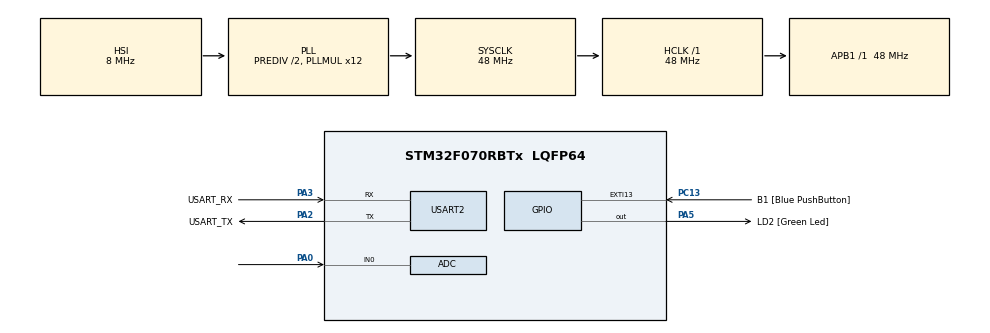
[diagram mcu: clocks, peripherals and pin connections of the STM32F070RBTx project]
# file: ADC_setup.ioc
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ADC.SamplingTime=ADC_SAMPLETIME_71CYCLES_5
Mcu.Family=STM32F0
Mcu.Name=STM32F070RBTx
Mcu.Package=LQFP64
PA0.Mode=IN0
PA0.Signal=ADC_IN0
PA13.GPIO_Label=TMS
PA13.Mode=Serial_Wire
PA13.Signal=SYS_SWDIO
PA14.GPIO_Label=TCK
PA14.Mode=Serial_Wire
PA14.Signal=SYS_SWCLK
PA2.GPIO_Label=USART_TX
PA2.Mode=Asynchronous
PA2.Signal=USART2_TX
PA3.GPIO_Label=USART_RX
PA3.Mode=Asynchronous
PA3.Signal=USART2_RX
PA5.GPIO_Label=LD2 [Green Led]
PA5.Signal=GPIO_Output
PC13.GPIO_Label=B1 [Blue PushButton]
PC13.GPIO_ModeDefaultEXTI=GPIO_MODE_IT_FALLING
PC13.Signal=GPXTI13
PC14-OSC32_IN.GPIO_Label=RCC_OSC32_IN
PC14-OSC32_IN.Mode=LSE-External-Oscillator
PC14-OSC32_IN.Signal=RCC_OSC32_IN
PC15-OSC32_OUT.GPIO_Label=RCC_OSC32_OUT
PC15-OSC32_OUT.Mode=LSE-External-Oscillator
PC15-OSC32_OUT.Signal=RCC_OSC32_OUT
PF0-OSC_IN.GPIO_Label=RCC_OSC_IN
PF0-OSC_IN.Mode=HSE-External-Clock-Source
PF0-OSC_IN.Signal=RCC_OSC_IN
PF1-OSC_OUT.GPIO_Label=RCC_OSC_OUT
PF1-OSC_OUT.Signal=RCC_OSC_OUT
ProjectManager.HeapSize=0x200
ProjectManager.StackSize=0x400
ProjectManager.TargetToolchain=STM32CubeIDE
RCC.AHBFreq_Value=48000000
RCC.APB1Freq_Value=48000000
RCC.APB1TimFreq_Value=48000000
RCC.HCLKFreq_Value=48000000
RCC.HSI48State-ClockTree=RCC_HSI48_ON
RCC.PLLDivider=RCC_PREDIV_DIV2
RCC.PLLMUL=RCC_PLL_MUL12
RCC.SYSCLKFreq_VALUE=48000000
RCC.SYSCLKSource=RCC_SYSCLKSOURCE_PLLCLK
USART2.VirtualMode-Asynchronous=VM_ASYNC
board=NUCLEO-F070RB

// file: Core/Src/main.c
/* USER CODE BEGIN Header */
/**
  ******************************************************************************
  * @file           : main.c
  * @brief          : Main program body
  ******************************************************************************
  * @attention
  *
  * Copyright (c) 2025 STMicroelectronics.
  * All rights reserved.
  *
  * This software is licensed under terms that can be found in the LICENSE file
  * in the root directory of this software component.
  * If no LICENSE file comes with this software, it is provided AS-IS.
  *
  ******************************************************************************
  */
/* USER CODE END Header */
#include "main.h"
#include "adc.h"
#include "usart.h"
#include "gpio.h"
#include <stdio.h>

void SystemClock_Config(void);

/* USER CODE BEGIN 0 */
int _write(int file, char *ptr, int len) {
    HAL_UART_Transmit(&huart2, (uint8_t *)ptr, len, HAL_MAX_DELAY);
    return len;
}
/* USER CODE END 0 */

int main(void)
{

  uint32_t adc_value;
  float moisture_percentage;
//  char buffer[50];

  HAL_Init();
  SystemClock_Config();
  MX_GPIO_Init();
  MX_USART2_UART_Init();
  MX_ADC_Init();
  /* USER CODE BEGIN 2 */
  // Calibrate ADC for better accuracy
  HAL_ADCEx_Calibration_Start(&hadc);
  /* USER CODE END 2 */

  /* Infinite loop */
  /* USER CODE BEGIN WHILE */
  while (1)
  {
	  // Start ADC conversion on PA0 (connected to sensor AO)
	      HAL_ADC_Start(&hadc);
	      HAL_ADC_PollForConversion(&hadc, HAL_MAX_DELAY); // Wait for conversion to complete
	      adc_value = HAL_ADC_GetValue(&hadc); // Read the 12-bit ADC value (0-4095)
	      HAL_ADC_Stop(&hadc); // Stop ADC to save power

	      // Map ADC value to moisture percentage (calibrate based on your sensor)
	      // Example: 4095 = dry (0%), 0 = wet (100%) - adjust after testing
	      if (adc_value > 4095) adc_value = 4095; // Clamp to max
	      if (adc_value < 0) adc_value = 0;       // Clamp to min
	      moisture_percentage = 100.0 - ((adc_value / 4095.0) * 100.0);

	      // Print results to serial monitor
	      printf("ADC Value: %lu, Moisture: %.2f%%\r\n", adc_value, moisture_percentage);
	      HAL_Delay(1000); // Wait 1 second before next reading
	      /* USER CODE END WHILE */  }
  /* USER CODE END 3 */
}

void SystemClock_Config(void)
{
  RCC_OscInitTypeDef RCC_OscInitStruct = {0};
  RCC_ClkInitTypeDef RCC_ClkInitStruct = {0};

  /** Initializes the RCC Oscillators according to the specified parameters
  * in the RCC_OscInitTypeDef structure.
  */
  RCC_OscInitStruct.OscillatorType = RCC_OSCILLATORTYPE_HSI|RCC_OSCILLATORTYPE_HSI14;
  RCC_OscInitStruct.HSIState = RCC_HSI_ON;
  RCC_OscInitStruct.HSI14State = RCC_HSI14_ON;
  RCC_OscInitStruct.HSICalibrationValue = RCC_HSICALIBRATION_DEFAULT;
  RCC_OscInitStruct.HSI14CalibrationValue = 16;
  RCC_OscInitStruct.PLL.PLLState = RCC_PLL_ON;
  RCC_OscInitStruct.PLL.PLLSource = RCC_PLLSOURCE_HSI;
  RCC_OscInitStruct.PLL.PLLMUL = RCC_PLL_MUL12;
  RCC_OscInitStruct.PLL.PREDIV = RCC_PREDIV_DIV2;
  if (HAL_RCC_OscConfig(&RCC_OscInitStruct) != HAL_OK)
  {
    Error_Handler();
  }

  /** Initializes the CPU, AHB and APB buses clocks
  */
  RCC_ClkInitStruct.ClockType = RCC_CLOCKTYPE_HCLK|RCC_CLOCKTYPE_SYSCLK
                              |RCC_CLOCKTYPE_PCLK1;
  RCC_ClkInitStruct.SYSCLKSource = RCC_SYSCLKSOURCE_PLLCLK;
  RCC_ClkInitStruct.AHBCLKDivider = RCC_SYSCLK_DIV1;
  RCC_ClkInitStruct.APB1CLKDivider = RCC_HCLK_DIV1;

  if (HAL_RCC_ClockConfig(&RCC_ClkInitStruct, FLASH_LATENCY_1) != HAL_OK)
  {
    Error_Handler();
  }
}

void Error_Handler(void)
{
  __disable_irq();
  while (1)
  {
  }
}
